# MEC1322 register map
Vendor: Microchip Technology Inc.; Series: ARMCM4F; File version: 1.0
CPU: CM4 r1p0, little endian, MPU, FPU, 3 interrupt priority bits
Registers are 32-bit, read-write, reset 0x0 unless marked. A register's access mark holds for its fields unless they carry their own. Offsets are from the block's base; [hi:lo] are bit positions; {n}, {i} and the like mark numbered series; 'fields as' and 'values as' point back to an identical list.

## PORT92 — The registers listed in the Configuration Register Summary table are for a single instance of the Legacy Port92/GATEA20 logic.
Base 0x400F1800
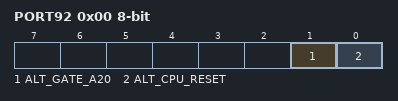
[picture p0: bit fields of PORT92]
0x00 PORT92 8-bit — PORT92 Register: The registers listed in the Runtime Register Summary table are for a single instance of the Legacy Port92/GATEA20 logic.
  [1] ALT_GATE_A20 — ALT_GATE_A20 This bit provides an alternate means for system control of the GATEA20 pin.
  [0] ALT_CPU_RESET — ALT_CPU_RESET This bit provides an alternate means to generate a CPU_RESET pulse.
0x100 GATEA20 8-bit — GATEA20 Control Register [0:0] GATEA20 0=The GATEA20 output is driven low, 1=The GATEA20 output is driven high
0x108 SETGA20L 8-bit write — SETGA20L Register A write to this register sets GATEA20 in the GATEA20 Control Register.
0x10C RSTGA20L 8-bit — RSTGA20L Register A write to this register sets GATEA20 in the GATEA20 Control Register.
0x330 PORT92_ENABLE 8-bit — PORT92 Enable Register [0:0] P92_EN When this bit is '1', the Port92h Register is enabled. When this bit is '0', the Port92h Register is disabled, and Host writes to LPC address 92h are ignored.

## MBX — The Mailbox provides a standard run-time mechanism for the host to communicate with the Embedded Controller (EC)
Base 0x400F2400
0x00 INDEX 8-bit — MBX_Index Register
0x04 DATA 8-bit — MBX_Data_Register
0x100 HOST_TO_EC (reset mask 0xFF) — If enabled, an interrupt to the EC marked by the MBX_DATA bit in the Interrupt Aggregator will be generated whenever the Host writes this register. This register is cleared when written with FFh.
0x104 EC_TO_HOST 8-bit — An EC write to this register will set bit EC_WR in the SMI Interrupt Source Register to '1b'. If enabled, this will generate a Host SMI. This register is cleared when written with FFh.
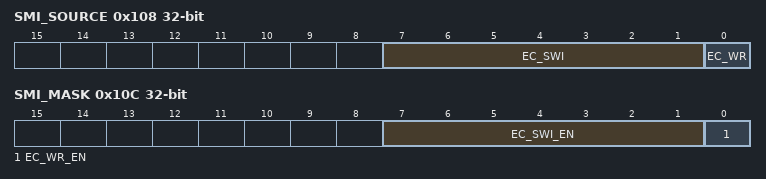
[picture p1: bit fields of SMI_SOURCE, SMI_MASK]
0x108 SMI_SOURCE — SMI Interrupt Source Register
  [7:1] EC_SWI — EC Software Interrupt. An SIRQ to the Host is generated when any bit in this register when this bit is set to '1b' and the corresponding bit in the SMI Interrupt Mask Register register is '1b'.
  [0] EC_WR ro — EC Mailbox Write. This bit is set automatically when the EC-to-Host Mailbox Register has been written. An SMI or SIRQ to the Host is generated when n this bit is '1b' and the corresponding bit in the SMI Interrupt Mask Register register is '1b'. This bit is automatically cleared by a read of the EC-to-Host Mailbox Register through the Host Access Port.
0x10C SMI_MASK — SMI Interrupt Mask Register
  [7:1] EC_SWI_EN — EC Software Interrupt Enable. If this bit is '1b', the bit EC_WR in the SMI Interrupt Source Register is enabled for the generation of SIRQ or nSMI events.
  [0] EC_WR_EN — EC Mailbox Write.Interrupt Enable. Each bit in this field that is '1b' enables the generation of SIRQ interrupts when the corresponding bit in the EC_SWI field in the SMI Interrupt Source Register is '1b'.
{0x110+4i} REG[{i}] (i=0..10) — Mailbox Register

## PM1 — The MEC1322 implements the ACPI fixed registers but includes only those bits that apply to the power button sleep button and RTC alarm events. The ACPI WAK_STS, SLP_TYP, and SLP_EN bits are also supported.
Base 0x400F1400
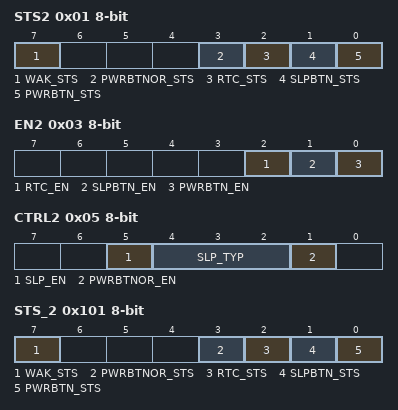
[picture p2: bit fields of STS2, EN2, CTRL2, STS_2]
0x01 STS2 8-bit — PM1 Status 2
  [7] WAK_STS — WAK_STS This bit can be set or cleared by the EC. The Host writing a one to this bit can also clear this bit. (R/WC)
  [3] PWRBTNOR_STS — PWRBTNOR_STS This bit can be set or cleared by the EC to simulate a Power button override event status if the power is controlled by the EC. (R/WC)
  [2] RTC_STS — RTC_STS This bit can be set or cleared by the EC to simulate a RTC status. (R/WC)
  [1] SLPBTN_STS — SLPBTN_STS This bit can be set or cleared by the EC to simulate a Sleep button status if the sleep state is controlled by the EC. (R/WC)
  [0] PWRBTN_STS — PWRBTN_STS This bit can be set or cleared by the EC to simulate a Power button status if the power is controlled by the EC. (R/WC)
0x03 EN2 8-bit — PM1 Enable 2
  [2] RTC_EN — RTC_EN This bit can be read or written by the Host. It can be read by the EC.
  [1] SLPBTN_EN — SLPBTN_EN This bit can be read or written by the Host. It can be read by the EC.
  [0] PWRBTN_EN — PWRBTN_EN This bit can be read or written by the Host. It can be read by the EC.
0x05 CTRL2 8-bit — PM1 Control 2
  [5] SLP_EN
  [4:2] SLP_TYP — SLP_TYP These bits can be set or cleared by the Host, read by the EC.
  [1] PWRBTNOR_EN — PWRBTNOR_EN This bit can be set or cleared by the Host, read by the EC.
0x101 STS_2 8-bit — PM1 Status 2
  fields as STS2
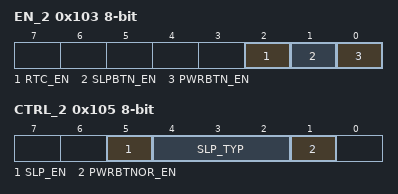
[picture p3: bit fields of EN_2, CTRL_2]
0x103 EN_2 8-bit — PM1 Enable 2
  fields as EN2
0x105 CTRL_2 8-bit — PM1 Control 2
  fields as CTRL2
0x110 PM_STS 8-bit — PM1 EC PM Status [0:0] EC_SCI_STS, If the EC_SCI_STS bit is '1', an interrupt is generated on the EC_SCI# pin.
